# G32R501 register map
Vendor: Geehy Semiconductor Co., Ltd.; Series: G32R5; File version: 1.0
CPU: CM55 r0p1, little endian, MPU, FPU, double-precision FPU, DSP, VTOR, 4 interrupt priority bits
Registers are 32-bit, read-write, reset 0x0 unless marked. A register's access mark holds for its fields unless they carry their own. Offsets are from the block's base; [hi:lo] are bit positions; {n}, {i} and the like mark numbered series.

## INPUTX_BAR — Input X-BAR (XBAR_INPUT)
Base 0x40030C00
0x00 INPUT1SELECT 16-bit reset 0xFFFE — INPUT1 Input Select Register
  [15:0] SELECT — Select GPIO for INPUT1 signal
0x02 INPUT2SELECT 16-bit reset 0xFFFE — INPUT2 Input Select Register
  [15:0] SELECT — Select GPIO for INPUT2 signal
0x04 INPUT3SELECT 16-bit reset 0xFFFE — INPUT3 Input Select Register
  [15:0] SELECT — Select GPIO for INPUT3 signal
0x06 INPUT4SELECT 16-bit reset 0xFFFE — INPUT4 Input Select Register
  [15:0] SELECT — Select GPIO for INPUT4 signal
0x08 INPUT5SELECT 16-bit reset 0xFFFE — INPUT5 Input Select Register
  [15:0] SELECT — Select GPIO for INPUT5 signal
0x0A INPUT6SELECT 16-bit reset 0xFFFE — INPUT6 Input Select Register
  [15:0] SELECT — Select GPIO for INPUT6 signal
0x0C INPUT7SELECT 16-bit reset 0xFFFE — INPUT7 Input Select Register
  [15:0] SELECT — Select GPIO for INPUT7 signal
0x0E INPUT8SELECT 16-bit reset 0xFFFE — INPUT8 Input Select Register
  [15:0] SELECT — Select GPIO for INPUT8 signal
0x10 INPUT9SELECT 16-bit reset 0xFFFE — INPUT9 Input Select Register
  [15:0] SELECT — Select GPIO for INPUT9 signal
0x12 INPUT10SELECT 16-bit reset 0xFFFE — INPUT10 Input Select Register
  [15:0] SELECT — Select GPIO for INPUT10 signal
0x14 INPUT11SELECT 16-bit reset 0xFFFE — INPUT11 Input Select Register
  [15:0] SELECT — Select GPIO for INPUT11 signal
0x16 INPUT12SELECT 16-bit reset 0xFFFE — INPUT12 Input Select Register
  [15:0] SELECT — Select GPIO for INPUT12 signal
0x18 INPUT13SELECT 16-bit reset 0xFFFE — INPUT13 Input Select Register
  [15:0] SELECT — Select GPIO for INPUT13 signal
0x1A INPUT14SELECT 16-bit reset 0xFFFE — INPUT14 Input Select Register
  [15:0] SELECT — Select GPIO for INPUT14 signal
0x1C INPUT15SELECT 16-bit reset 0xFFFE — INPUT15 Input Select Register
  [15:0] SELECT — Select GPIO for INPUT15 signal
0x1E INPUT16SELECT 16-bit reset 0xFFFE — INPUT16 Input Select Register
  [15:0] SELECT — Select GPIO for INPUT16 signal
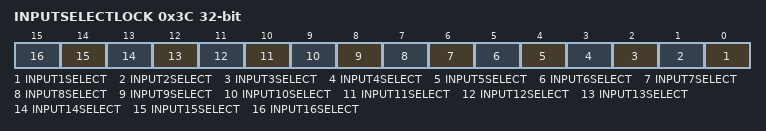
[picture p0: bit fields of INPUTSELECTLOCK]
0x3C INPUTSELECTLOCK rw-once
  [n-1] INPUT{n}SELECT (n=1..16) — Lock bit for INPUT{n}SELECT Register

## PWM_XBAR — PWM X-BAR (XBAR_PWM)
Base 0x400311C0
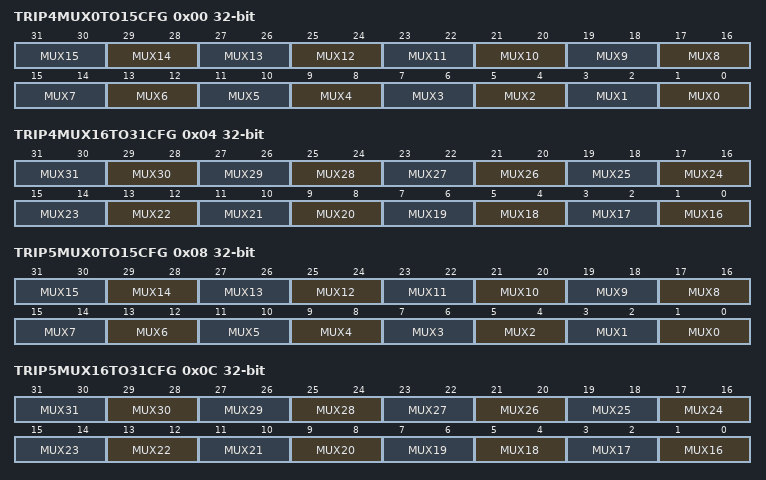
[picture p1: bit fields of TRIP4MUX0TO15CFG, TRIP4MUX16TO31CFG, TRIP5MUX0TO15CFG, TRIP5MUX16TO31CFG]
0x00 TRIP4MUX0TO15CFG — PWM XBAR Mux Configuration for TRIP4
  [2n+1:2n] MUX{n} (n=0..15) — Mux{n} Configuration for TRIP4 of PWM-XBAR
0x04 TRIP4MUX16TO31CFG — PWM XBAR Mux Configuration for TRIP4
  [2n-31:2n-32] MUX{n} (n=16..31) — Mux{n} Configuration for TRIP4 of PWM-XBAR
0x08 TRIP5MUX0TO15CFG — PWM XBAR Mux Configuration for TRIP5
  [2n+1:2n] MUX{n} (n=0..15) — Mux{n} Configuration for TRIP5 of PWM-XBAR
0x0C TRIP5MUX16TO31CFG — PWM XBAR Mux Configuration for TRIP5
  [2n-31:2n-32] MUX{n} (n=16..31) — Mux{n} Configuration for TRIP5 of PWM-XBAR
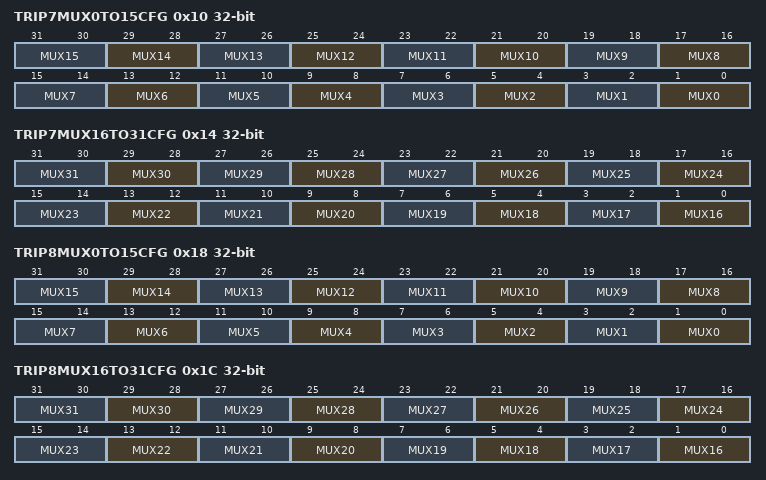
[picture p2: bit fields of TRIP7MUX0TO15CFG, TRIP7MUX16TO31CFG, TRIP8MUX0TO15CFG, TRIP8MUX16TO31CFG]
0x10 TRIP7MUX0TO15CFG — PWM XBAR Mux Configuration for TRIP7
  [2n+1:2n] MUX{n} (n=0..15) — Mux{n} Configuration for TRIP7 of PWM-XBAR
0x14 TRIP7MUX16TO31CFG — PWM XBAR Mux Configuration for TRIP7
  [2n-31:2n-32] MUX{n} (n=16..31) — Mux{n} Configuration for TRIP7 of PWM-XBAR
0x18 TRIP8MUX0TO15CFG — PWM XBAR Mux Configuration for TRIP8
  [2n+1:2n] MUX{n} (n=0..15) — Mux{n} Configuration for TRIP8 of PWM-XBAR
0x1C TRIP8MUX16TO31CFG — PWM XBAR Mux Configuration for TRIP8
  [2n-31:2n-32] MUX{n} (n=16..31) — Mux{n} Configuration for TRIP8 of PWM-XBAR
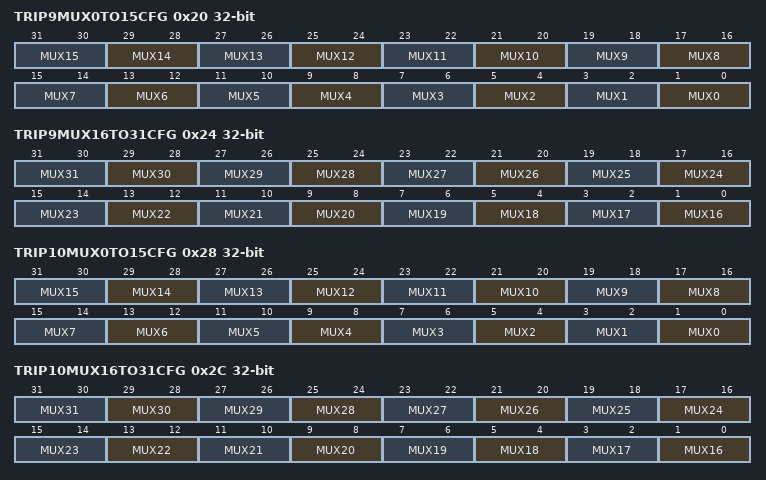
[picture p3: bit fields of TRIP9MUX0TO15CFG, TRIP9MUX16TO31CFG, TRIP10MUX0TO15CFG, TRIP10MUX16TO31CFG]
0x20 TRIP9MUX0TO15CFG — PWM XBAR Mux Configuration for TRIP9
  [2n+1:2n] MUX{n} (n=0..15) — Mux{n} Configuration for TRIP9 of PWM-XBAR
0x24 TRIP9MUX16TO31CFG — PWM XBAR Mux Configuration for TRIP9
  [2n-31:2n-32] MUX{n} (n=16..31) — Mux{n} Configuration for TRIP9 of PWM-XBAR
0x28 TRIP10MUX0TO15CFG — PWM XBAR Mux Configuration for TRIP10
  [2n+1:2n] MUX{n} (n=0..15) — Mux{n} Configuration for TRIP10 of PWM-XBAR
0x2C TRIP10MUX16TO31CFG — PWM XBAR Mux Configuration for TRIP10
  [2n-31:2n-32] MUX{n} (n=16..31) — Mux{n} Configuration for TRIP10 of PWM-XBAR
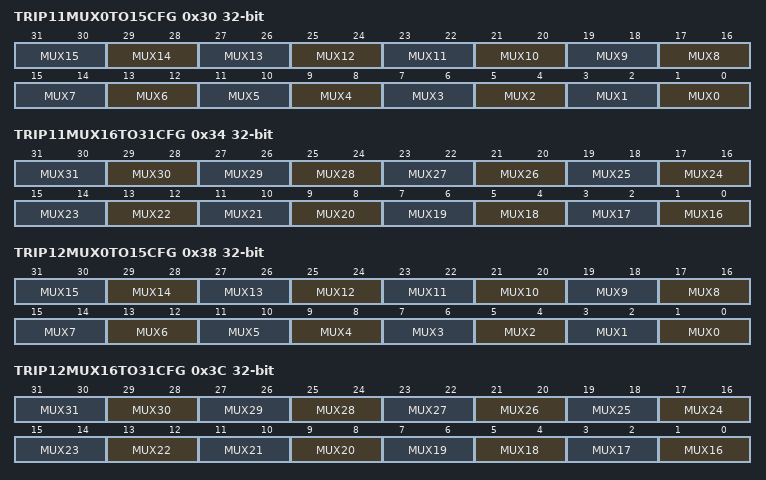
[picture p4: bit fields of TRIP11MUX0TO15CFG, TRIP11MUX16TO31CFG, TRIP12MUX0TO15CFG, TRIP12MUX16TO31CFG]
0x30 TRIP11MUX0TO15CFG — PWM XBAR Mux Configuration for TRIP11
  [2n+1:2n] MUX{n} (n=0..15) — Mux{n} Configuration for TRIP11 of PWM-XBAR
0x34 TRIP11MUX16TO31CFG — PWM XBAR Mux Configuration for TRIP11
  [2n-31:2n-32] MUX{n} (n=16..31) — Mux{n} Configuration for TRIP11 of PWM-XBAR
0x38 TRIP12MUX0TO15CFG — PWM XBAR Mux Configuration for TRIP12
  [2n+1:2n] MUX{n} (n=0..15) — Mux{n} Configuration for TRIP12 of PWM-XBAR
0x3C TRIP12MUX16TO31CFG — PWM XBAR Mux Configuration for TRIP12
  [2n-31:2n-32] MUX{n} (n=16..31) — Mux{n} Configuration for TRIP12 of PWM-XBAR
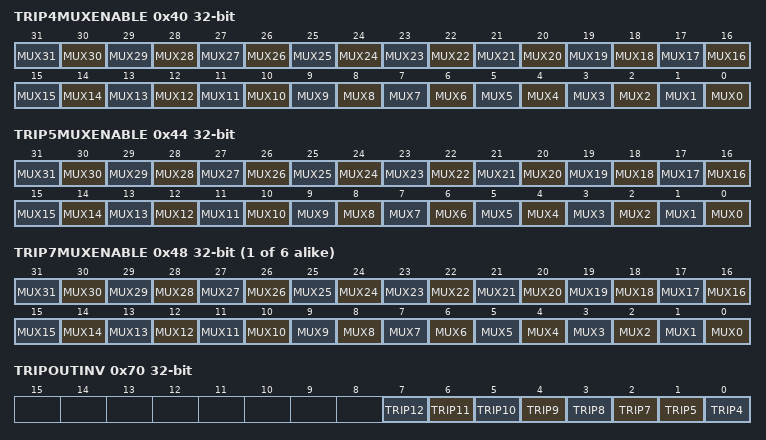
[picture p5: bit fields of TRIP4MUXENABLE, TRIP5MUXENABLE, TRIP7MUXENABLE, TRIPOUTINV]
0x40 TRIP4MUXENABLE — PWM XBAR Mux Enable for TRIP4
  [n] MUX{n} (n=0..31) — Mux{n} drive for TRIP4 of PWM-XBAR
0x44 TRIP5MUXENABLE — PWM XBAR Mux Enable for TRIP5
  [n] MUX{n} (n=0..31) — Mux{n} drive for TRIP5 of PWM-XBAR
{0x2C+4i} TRIP{i}MUXENABLE (i=7..12) — PWM XBAR Mux Enable for TRIP{i}
  [n] MUX{n} (n=0..31) — Mux{n} drive for TRIP{i} of PWM-XBAR
0x70 TRIPOUTINV — PWM XBAR Output Inversion Register
  [n-5] TRIP{n} (n=7..12) — Selects polarity for TRIP{n} of PWM-XBAR
  [1] TRIP5 — Selects polarity for TRIP5 of PWM-XBAR
  [0] TRIP4 — Selects polarity for TRIP4 of PWM-XBAR
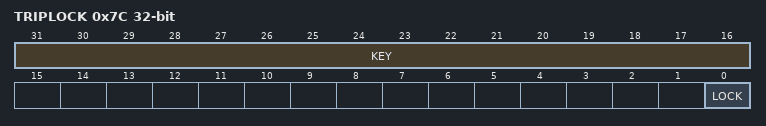
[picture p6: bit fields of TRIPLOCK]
0x7C TRIPLOCK access per field — PWM XBAR Configuration Lock register
  [31:16] KEY rw — Write protection KEY
  [0] LOCK rw-once — Locks the configuration for PWM-XBAR
